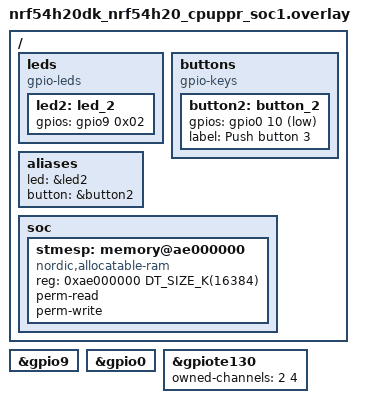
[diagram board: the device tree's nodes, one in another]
/*
 * Copyright (c) 2023 Nordic Semiconductor ASA
 *
 * SPDX-License-Identifier: Apache-2.0
 */

 / {
	leds {
		compatible = "gpio-leds";
		led2: led_2 {
			gpios = < &gpio9 0x02 GPIO_ACTIVE_HIGH >;
		};
	};

	buttons {
		compatible = "gpio-keys";
		button2: button_2 {
			gpios = <&gpio0 10 (GPIO_PULL_UP | GPIO_ACTIVE_LOW)>;
			label = "Push button 3";
		};
	};

	aliases {
		led = &led2;
		button = &button2;
	};

	soc {
		stmesp: memory@ae000000 {
			compatible = "nordic,allocatable-ram";
			reg = <0xae000000 DT_SIZE_K(16384)>;
			perm-read;
			perm-write;
		};
	};
};

&gpio9 {
	status = "okay";
};

&gpio0 {
	status = "okay";
};

&gpiote130 {
	owned-channels = <2 4>;
	status = "okay";
};
